# tviic2d6mddr register map
Vendor: Cypress Semiconductor; Series: tviic2d6mddr; File version: 1.0
CPU: CM7 r0p1, little endian, MPU, FPU, VTOR, 3 interrupt priority bits
Registers are 32-bit, read-write, reset 0x0 unless marked. A register's access mark holds for its fields unless they carry their own. Offsets are from the block's base; lines under a group give offsets from that group; [hi:lo] are bit positions; {n}, {i} and the like mark numbered series; 'fields as' and 'values as' point back to an identical list; <NAME> marks a mode.

## Memory map
0x40000000 PERI size 0x10000 — Peripheral interconnect
0x40020000 PERI_MS size 0x20000 — Peripheral interconnect, master interface
0x40040000 PERI_PCLK size 0x20000 — Peripheral PCLK groups
0x40100000 CRYPTO size 0x10000 — Cryptography component
0x40200000 CPUSS size 0x10000 — CPU subsystem (CPUSS)
0x40210000 FAULT size 0x10000 — Fault structures
0x40220000 IPC size 0x10000
0x40230000 PROT size 0x10000 — Protection
0x40240000 FLASHC size 0x10000 — Flash controller
0x40260000 SRSS size 0x10000 — SRSS Core Registers (ver3p3)
0x40270000 BACKUP size 0x10000 — SRSS Backup Domain (ver3p3)
0x40280000 DW0 size 0x10000 — Datawire Controller
0x40290000 DW1 size 0x10000
0x402A0000 DMAC size 0x10000
0x402B0000 AXI_DMAC size 0x10000
0x402C0000 EFUSE size 0x200 — EFUSE MXS40 registers
0x402C0800 EFUSE_DATA size 0x200 — eFUSE memory
0x40300000 HSIOM size 0x4000 — High Speed IO Matrix (HSIOM)
0x40310000 GPIO size 0x10000 — GPIO port control/configuration
0x40320000 SMARTIO size 0x10000 — Programmable IO configuration
0x40380000 TCPWM0 size 0x20000 — Timer/Counter/PWM
0x403F0000 EVTGEN0 size 0x1000 — Event generator
0x40400000 SMIF0 size 0x40000 — SMIF subsystem (bridge + 2 core SMIFs, OR no bridge and 1 core SMIF)
0x40460000 SDHC0 size 0x10000 — SD/eMMC Host Controller
0x40480000 ETH0 size 0x10000 — Ethernet Interface
0x404A0000 LPDDR40 size 0x8000 — LPDDR4
0x40500000 LIN0 size 0x10000 — LIN
0x40510000 CXPI0 size 0x10000 — CXPI
0x40520000 CANFD0 size 0x20000 — CAN Controller
0x40540000 CANFD1 size 0x20000
0x40600000 SCB0 size 0x10000 — Serial Communications Block (SPI/UART/I2C)
{0x40600000+0x10000*n} SCB{n} size 0x10000 (n=1..11)
0x40810000 TDM0 size 0x10000 — TDM
0x40820000 SG0 size 0x10000 — SG
0x40830000 PWM0 size 0x10000 — PWM
0x40840000 DAC0 size 0x100 — DAC
0x40880000 MIXER0 size 0x10000 — MIXER
0x40890000 MIXER1 size 0x10000
0x40900000 PASS0 size 0x100000 — Programmable Analog Subsystem for S40E
0x40A00000 VIDEOSS0 size 0x100000 — Video and Graphics Subsystem IP
0x40B00000 PD size 0x400 — Power Domain and Switch Block
0x40B10000 JPEGDEC size 0x2000

## Interrupts
{n} CPUIntIdx{n} (CPUSS) (n=0..7) — CPU User Interrupt #{n}
{n+8} Internal{n} (CPUSS) (n=0..7) — Internal SW Interrupt #{n}

## EFUSE_DATA — eFUSE memory
Base 0x402C0800
{0x2C+4i} SECURE_HASH_WORD{i} (i=0..3) — Secure 128 bits HASH word {i} that is used for authentication in SECURE protection state.
  [31:0] HASH_WORD{i}
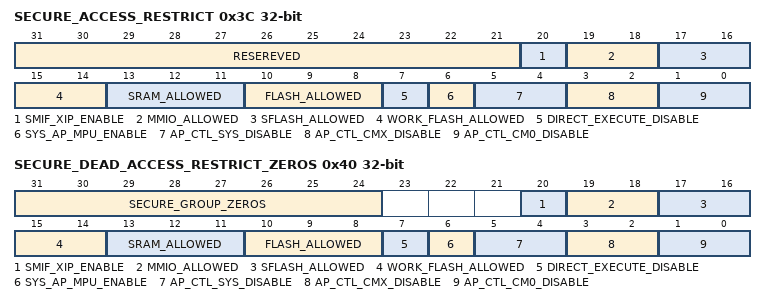
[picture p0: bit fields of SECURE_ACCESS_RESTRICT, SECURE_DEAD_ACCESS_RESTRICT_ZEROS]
0x3C SECURE_ACCESS_RESTRICT — Access restrictions for SECURE protection state in SECURE lifecycle stage
  [31:21] RESEREVED
  [20] SMIF_XIP_ENABLE — goes to SYS DAP MPU
  [19:18] MMIO_ALLOWED — goes to SYS DAP MPU
  [17:16] SFLASH_ALLOWED — goes to SYS DAP MPU
  [15:14] WORK_FLASH_ALLOWED — goes to SYS DAP MPU
  [13:11] SRAM_ALLOWED — goes to SYS DAP MPU
  [10:8] FLASH_ALLOWED — goes to SYS DAP MPU
  [7] DIRECT_EXECUTE_DISABLE — used by ROM boot
  [6] SYS_AP_MPU_ENABLE — goes to SYS DAP MPU
  [5:4] AP_CTL_SYS_DISABLE — goes to CPUSS.AP_CTL
  [3:2] AP_CTL_CMX_DISABLE — goes to CPUSS.AP_CTL
  [1:0] AP_CTL_CM0_DISABLE — goes to CPUSS.AP_CTL
0x40 SECURE_DEAD_ACCESS_RESTRICT_ZEROS — Access restrictions for DEAD protection state in SECURE lifecycle stage and number of zeros for Secure fuse group
  [31:24] SECURE_GROUP_ZEROS — number of zeros for Secure fuse group covers secure hash, secure access restriction, secure hash zeros, secure dead access restriction
  [20] SMIF_XIP_ENABLE — goes to SYS DAP MPU
  [19:18] MMIO_ALLOWED — goes to SYS DAP MPU
  [17:16] SFLASH_ALLOWED — goes to SYS DAP MPU
  [15:14] WORK_FLASH_ALLOWED — goes to SYS DAP MPU
  [13:11] SRAM_ALLOWED — goes to SYS DAP MPU
  [10:8] FLASH_ALLOWED — goes to SYS DAP MPU
  [7] DIRECT_EXECUTE_DISABLE — used by ROM boot
  [6] SYS_AP_MPU_ENABLE — goes to SYS DAP MPU
  [5:4] AP_CTL_SYS_DISABLE — goes to CPUSS.AP_CTL
  [3:2] AP_CTL_CMX_DISABLE — goes to CPUSS.AP_CTL
  [1:0] AP_CTL_CM0_DISABLE — goes to CPUSS.AP_CTL
{0x68+4i} CUSTOMER_DATA[{i}] (i=0..5) — Available EFUSE bits for customer usage.They can be programmed in NORMAL protection state via CMx/DAP and in SECURE protection state via CMx.
  [31:0] DATA_BYTE

## Licence text in the file
Copyright 2016-2019, Cypress Semiconductor Corporation. All rights reserved. You may use this file only in accordance with the license, terms, conditions, disclaimers, and limitations in the end user license agreement accompanying the software package with which this file was provided.
